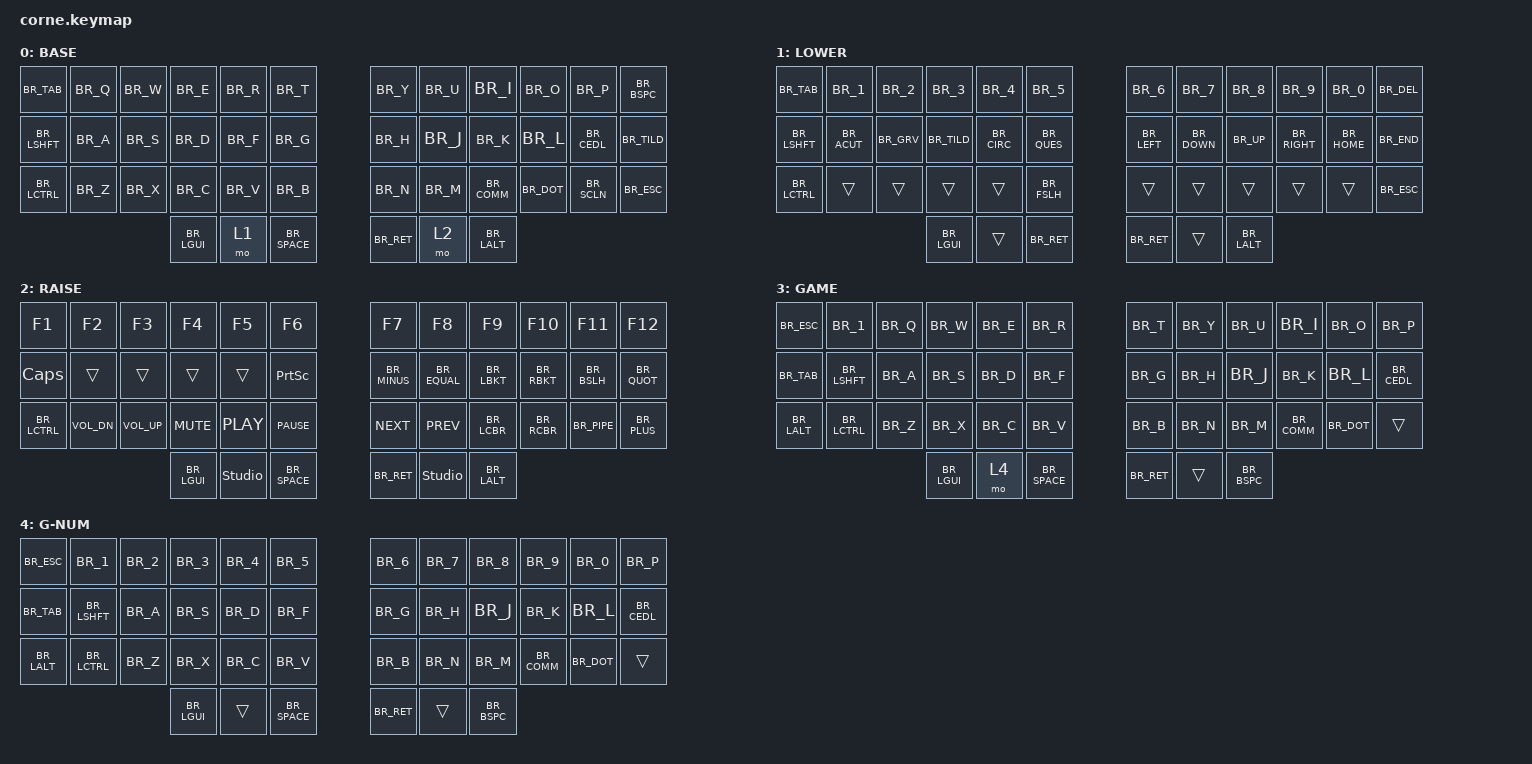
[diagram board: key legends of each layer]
/*
 * Copyright (c) 2020 The ZMK Contributors
 *
 * SPDX-License-Identifier: MIT
 */

#include <behaviors.dtsi>
#include <dt-bindings/zmk/bt.h>
#include <dt-bindings/zmk/keys.h>
#include <dt-bindings/zmk/mouse.h>
#include "keymap_brazilian_abnt2_zmk.h"

/ {
    combos {
        compatible = "zmk,combos";

        game_toggle: game_toggle {
            timeout-ms = <50>;
            key-positions = <37 40>; // LWR + RSE
            bindings = <&tog 3>; // Toggle GAME layer (layer 3)
        };

        // Bluetooth Controls - Combos para evitar ativação acidental
        bt_clear: bt_clear {
            timeout-ms = <100>;
            key-positions = <0 11>; // Tab + Backspace
            bindings = <&bt BT_CLR>;
        };

        bt_profile_1: bt_profile_1 {
            timeout-ms = <100>;
            key-positions = <0 1>; // Tab + Q = Perfil 1
            bindings = <&bt BT_SEL 0>;
        };

        bt_profile_2: bt_profile_2 {
            timeout-ms = <100>;
            key-positions = <0 2>; // Tab + W = Perfil 2
            bindings = <&bt BT_SEL 1>;
        };

        bt_profile_3: bt_profile_3 {
            timeout-ms = <100>;
            key-positions = <0 3>; // Tab + E = Perfil 3
            bindings = <&bt BT_SEL 2>;
        };

        bt_profile_4: bt_profile_4 {
            timeout-ms = <100>;
            key-positions = <0 4>; // Tab + R = Perfil 4
            bindings = <&bt BT_SEL 3>;
        };

        bt_profile_5: bt_profile_5 {
            timeout-ms = <100>;
            key-positions = <0 5>; // Tab + T = Perfil 5
            bindings = <&bt BT_SEL 4>;
        };
    };
    keymap {
        compatible = "zmk,keymap";

        default_layer {
            display-name = "BASE";
            // -----------------------------------------------------------------------------------------
            // | TAB  |  Q  |  W  |  E  |  R  |  T  |   |  Y  |  U   |  I  |  O  |  P  | BKSP |
            // | SHFT |  A  |  S  |  D  |  F  |  G  |   |  H  |  J   |  K  |  L  |  Ç  |  ~   |
            // | CTRL |  Z  |  X  |  C  |  V  |  B  |   |  N  |  M   |  ,  |  .  |  ;  | ESC  |
            //                    | GUI | LWR | SPC |   | ENT | RSE  | ALT |

            bindings = <
   BR_TAB     BR_Q  BR_W  BR_E  BR_R  BR_T       BR_Y  BR_U  BR_I     BR_O   BR_P    BR_BSPC
   BR_LSHFT   BR_A  BR_S  BR_D  BR_F  BR_G       BR_H  BR_J  BR_K     BR_L   BR_CEDL BR_TILD
   BR_LCTRL   BR_Z  BR_X  BR_C  BR_V  BR_B       BR_N  BR_M  BR_COMM  BR_DOT BR_SCLN BR_ESC
                          BR_LGUI &mo 1 BR_SPACE  BR_RET &mo 2 BR_LALT
            >;
        };

        lower_layer {
            display-name = "LOWER";
            // -----------------------------------------------------------------------------------------
            // | TAB  |  1  |  2  |  3  |  4  |  5  |   |  6  |  7  |  8  |  9  |  0  | DEL  |
            // | SHFT | ´   | `   | ~   | ^   | ?   |   | LFT | DWN |  UP | RGT | HOME| END  |
            // | CTRL |     |     |     |     | /   |   |     |     |     |     |     | ESC  |
            //                    | GUI |     | ENT |   | ENT |     | ALT |

            bindings = <
BR_TAB      BR_1          BR_2          BR_3          BR_4          BR_5            BR_6      BR_7      BR_8      BR_9       BR_0    BR_DEL
BR_LSHFT    BR_ACUT       BR_GRV        BR_TILD       BR_CIRC       BR_QUES         BR_LEFT   BR_DOWN   BR_UP     BR_RIGHT   BR_HOME BR_END
BR_LCTRL    &trans        &trans         &trans       &trans        BR_FSLH          &trans    &trans    &trans    &trans     &trans  BR_ESC
                                        BR_LGUI       &trans        BR_RET          BR_RET    &trans    BR_LALT
            >;
        };

        raise_layer {
            display-name = "RAISE";
            // -----------------------------------------------------------------------------------------
            // | F1   | F2  | F3  | F4  | F5  | F6  |   | F7  | F8  | F9  | F10 | F11 | F12  |
            // | CAPS |     |     |     |     |PRTSC|   |  -  |  =  |  [  |  ]  |  \  |  '   |
            // | CTRL |VOL -|VOL +|MUTE |PLAY |PAUSE|   |NEXT |PREV |  {  |  }  |  |  |  +   |
            //                    | GUI |STUDIO| SPC |  | ENT |STUDIO| ALT |
            //   STUDIO = desbloqueia o ZMK Studio (editor de keymap pelo navegador)
            // 
            // Bluetooth controls moved to combos:
            // Tab + Backspace = BT Clear
            // Tab + Q/W/E/R/T = BT Profiles 1/2/3/4/5

            bindings = <
&kp F1      &kp F2        &kp F3        &kp F4        &kp F5        &kp F6              &kp F7      &kp F8    &kp F9       &kp F10   &kp F11   &kp F12
&kp CAPS      &trans        &trans        &trans        &trans        &kp PSCRN              BR_MINUS   BR_EQUAL   BR_LBKT      BR_RBKT   BR_BSLH   BR_QUOT
BR_LCTRL    &kp C_VOL_DN  &kp C_VOL_UP  &kp C_MUTE    &kp C_PLAY    &kp C_PAUSE         &kp C_NEXT &kp C_PREV BR_LCBR      BR_RCBR   BR_PIPE   BR_PLUS
                                         BR_LGUI    &studio_unlock   BR_SPACE           BR_RET     &studio_unlock     BR_LALT
            >;
        };

        // Layer 3: Gaming (toggle via LWR+RSE combo). Default: fall-through to base.
        game_layer {
            display-name = "GAME";
            // -----------------------------------------------------------------------------------------
            // | ESC  |    1   |  Q  |  W  |  E  |  R  |   |  T  |  Y   |  U  |  I  |  O  |  P  |
            // | TAB  |  SHFT  |  A  |  S  |  D  |  F  |   |  G  |  H   |  J  |  K  |  L  |  Ç  |
            // | ALT  |  CTRL  |  Z  |  X  |  C  |  V  |   |  B  |  N   |  M  |  ,  |  .  |     |
            //                       | GUI |G-NUM| SPC |   | ENT |      |BKSP |
            //   G-NUM = segurar para a camada game_lower (números)
            bindings = <
    BR_ESC    BR_1      BR_Q     BR_W     BR_E     BR_R           BR_T     BR_Y     BR_U     BR_I     BR_O     BR_P
    BR_TAB    BR_LSHFT  BR_A     BR_S     BR_D     BR_F           BR_G     BR_H     BR_J     BR_K     BR_L     BR_CEDL
    BR_LALT   BR_LCTRL  BR_Z     BR_X     BR_C     BR_V           BR_B     BR_N     BR_M     BR_COMM  BR_DOT   &trans
                                 BR_LGUI  &mo 4    BR_SPACE       BR_RET   &trans   BR_BSPC
            >;
        };

        // Layer 4: Game layer com números na linha superior (ativada com LWR na game_layer)
        game_lower_layer {
            display-name = "G-NUM";
            // -----------------------------------------------------------------------------------------
            // | ESC  |  1     |  2  |  3  |  4  |  5  |   |  6  |  7   |  8  |  9  |  0  |  P  |
            // | TAB  |  SHFT  |  A  |  S  |  D  |  F  |   |  G  |  H   |  J  |  K  |  L  |  Ç  |
            // | ALT  |  CTRL  |  Z  |  X  |  C  |  V  |   |  B  |  N   |  M  |  ,  |  .  |     |
            //                       | GUI |     | SPC |   | ENT |      |BKSP |
            bindings = <
    BR_ESC    BR_1      BR_2     BR_3     BR_4     BR_5           BR_6     BR_7     BR_8     BR_9     BR_0     BR_P
    BR_TAB    BR_LSHFT  BR_A     BR_S     BR_D     BR_F           BR_G     BR_H     BR_J     BR_K     BR_L     BR_CEDL
    BR_LALT   BR_LCTRL  BR_Z     BR_X     BR_C     BR_V           BR_B     BR_N     BR_M     BR_COMM  BR_DOT   &trans
                                 BR_LGUI  &trans   BR_SPACE       BR_RET   &trans   BR_BSPC
            >;
        };
    };
};
